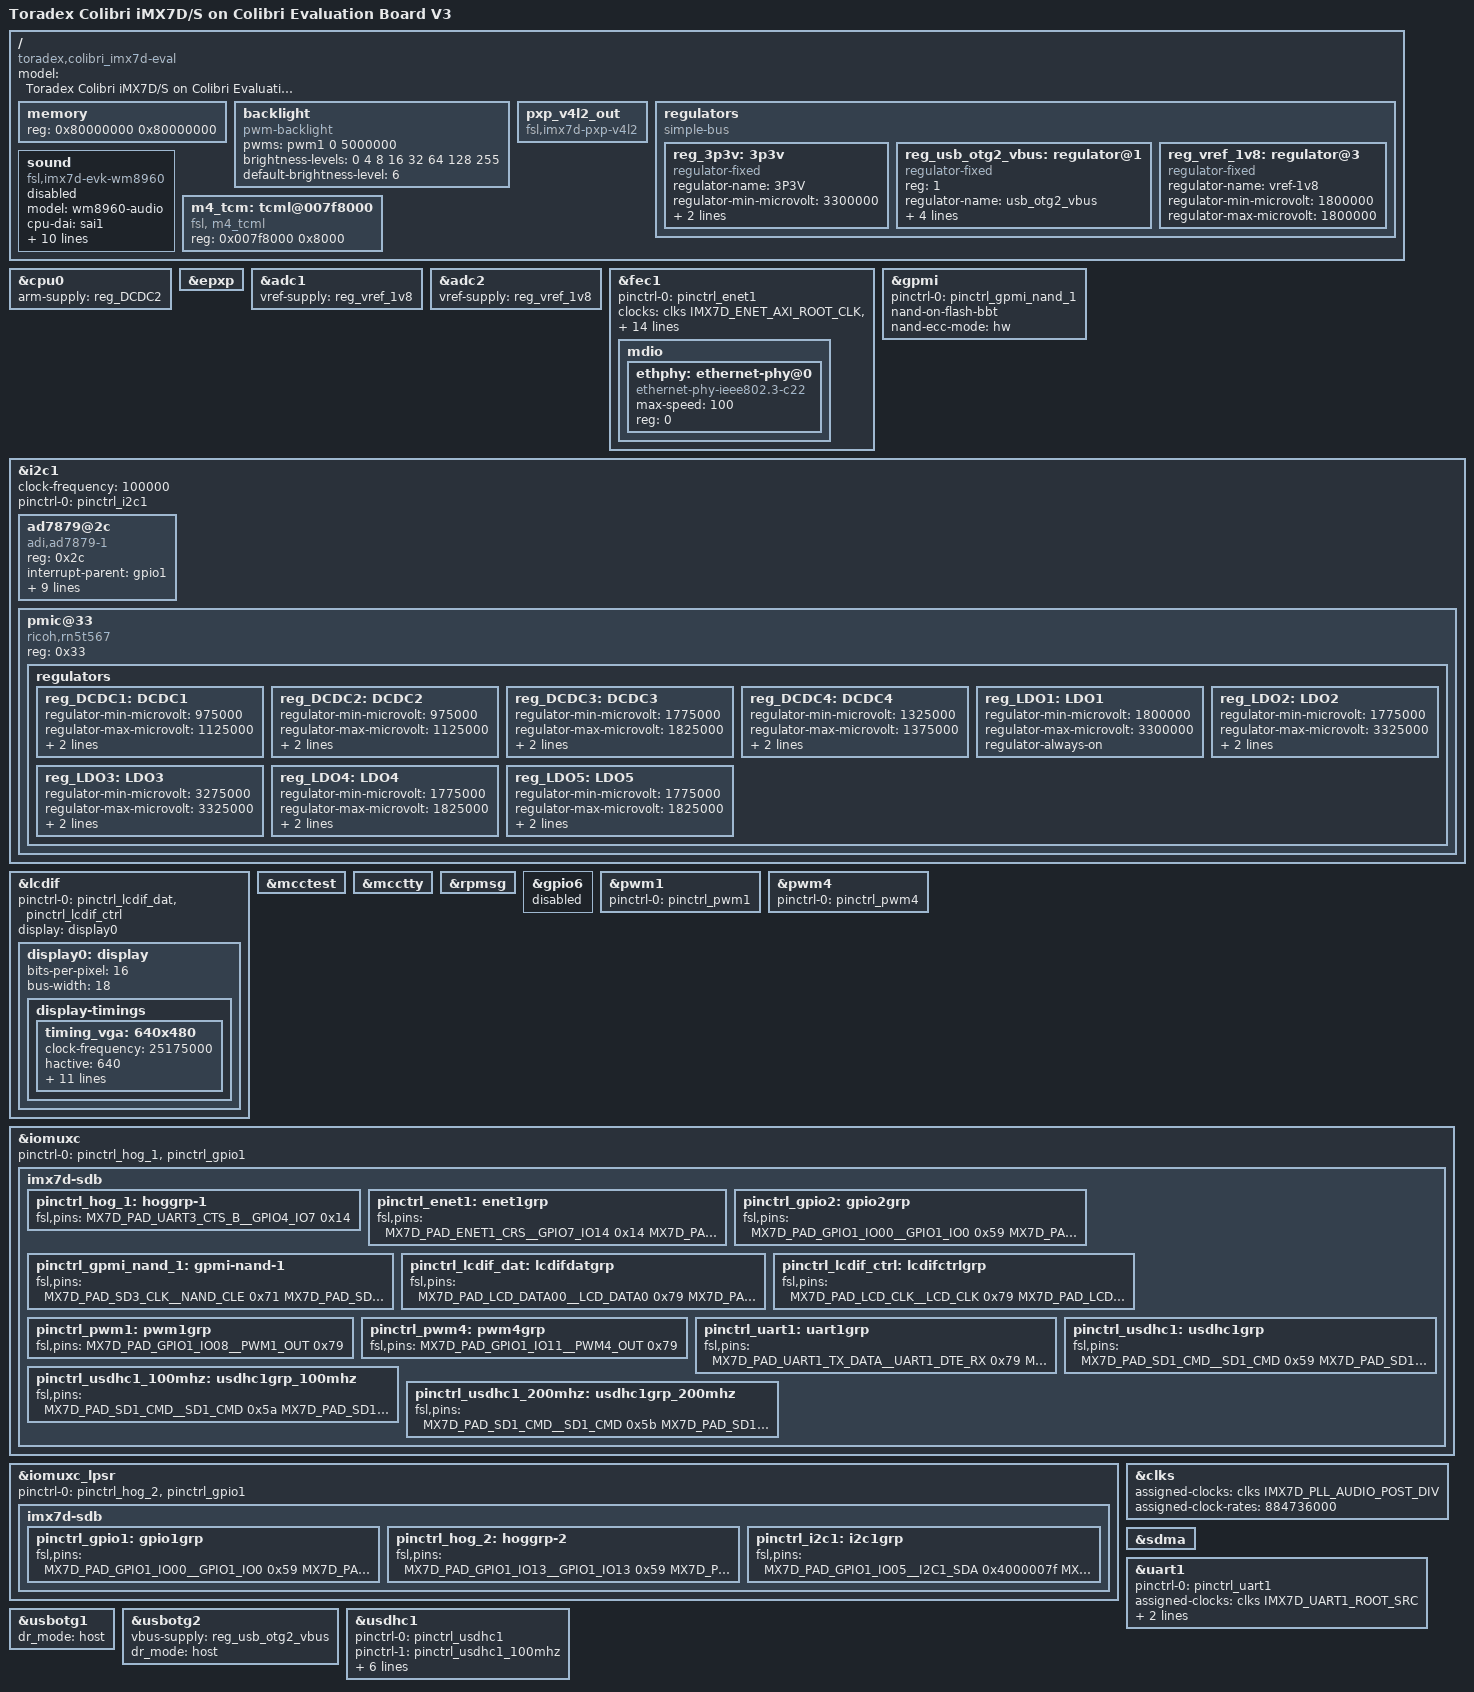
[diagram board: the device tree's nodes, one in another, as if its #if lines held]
/*
 * Copyright (C) 2015 Freescale Semiconductor, Inc.
 *
 * This program is free software; you can redistribute it and/or modify
 * it under the terms of the GNU General Public License version 2 as
 * published by the Free Software Foundation.
 */

/dts-v1/;

#include <dt-bindings/input/input.h>
#include "imx7d.dtsi"
//#define IMX7S 1
/ {
	model = "Toradex Colibri iMX7D/S on Colibri Evaluation Board V3";
	compatible = "toradex,colibri_imx7d-eval", "toradex,colibri_imx7d", "fsl,imx7d";

	memory {
		reg = <0x80000000 0x80000000>;
	};

#ifndef IMX7S
	backlight {
		compatible = "pwm-backlight";
		pwms = <&pwm1 0 5000000>;
		brightness-levels = <0 4 8 16 32 64 128 255>;
		default-brightness-level = <6>;
		status = "okay";
	};

	pxp_v4l2_out {
		compatible = "fsl,imx7d-pxp-v4l2", "fsl,imx6sx-pxp-v4l2", "fsl,imx6sl-pxp-v4l2";
		status = "okay";
	};
#endif
	regulators {
		compatible = "simple-bus";
		#address-cells = <1>;
		#size-cells = <0>;

		reg_3p3v: 3p3v {
			compatible = "regulator-fixed";
			regulator-name = "3P3V";
			regulator-min-microvolt = <3300000>;
			regulator-max-microvolt = <3300000>;
			regulator-always-on;
		};

		reg_usb_otg2_vbus: regulator@1 {
			compatible = "regulator-fixed";
			reg = <1>;
			regulator-name = "usb_otg2_vbus";
			regulator-min-microvolt = <5000000>;
			regulator-max-microvolt = <5000000>;
			gpio = <&gpio4 7 GPIO_ACTIVE_HIGH>;
			enable-active-low;
		};

		reg_vref_1v8: regulator@3 {
			compatible = "regulator-fixed";
			regulator-name = "vref-1v8";
			regulator-min-microvolt = <1800000>;
			regulator-max-microvolt = <1800000>;
		};
	};

#ifndef IMX7S
	sound {
		compatible = "fsl,imx7d-evk-wm8960",
			   "fsl,imx-audio-wm8960";
		model = "wm8960-audio";
		cpu-dai = <&sai1>;
		//audio-codec = <&codec>;
		codec-master;
		/* JD2: hp detect high for headphone*/
		hp-det = <2 0>;
		audio-routing =
			"LINPUT1", "Main MIC",
			"Main MIC", "MICB";
		assigned-clocks = <&clks IMX7D_AUDIO_MCLK_ROOT_SRC>,
				  <&clks IMX7D_AUDIO_MCLK_ROOT_CLK>;
		assigned-clock-parents = <&clks IMX7D_PLL_AUDIO_POST_DIV>;
		assigned-clock-rates = <0>, <12288000>;
		status = "disabled";
	};
#endif

	m4_tcm: tcml@007f8000 {
		compatible = "fsl, m4_tcml";
		reg = <0x007f8000 0x8000>;
	};
};

&cpu0 {
	arm-supply = <&reg_DCDC2>;
};
#ifndef IMX7S
&epxp {
	status = "okay";
};

&adc1 {
	vref-supply = <&reg_vref_1v8>;
	status = "okay";
};

&adc2 {
	vref-supply = <&reg_vref_1v8>;
	status = "okay";
};

&fec1 {
	pinctrl-names = "default";
	pinctrl-0 = <&pinctrl_enet1>;
	//pinctrl-assert-gpios = <&gpio_spi 5 GPIO_ACTIVE_HIGH>;
	clocks = <&clks IMX7D_ENET_AXI_ROOT_CLK>,
		<&clks IMX7D_ENET_AXI_ROOT_CLK>,
		<&clks IMX7D_ENET1_TIME_ROOT_CLK>,
		<&clks IMX7D_PLL_ENET_MAIN_50M_CLK>,
		<&clks IMX7D_ENET1_REF_ROOT_CLK>;
	clock-names = "ipg", "ahb", "ptp",
		"enet_clk_ref", "enet_out";

	assigned-clocks = <&clks IMX7D_ENET1_TIME_ROOT_SRC>,
			  <&clks IMX7D_ENET1_TIME_ROOT_CLK>;
	assigned-clock-parents = <&clks IMX7D_PLL_ENET_MAIN_100M_CLK>;
	assigned-clock-rates = <0>, <100000000>;
	phy-mode = "rmii";
	phy-handle = <&ethphy>;
	phy-supply = <&reg_LDO1>;
	fsl,magic-packet;
	status = "okay";

	mdio {
		#address-cells = <1>;
		#size-cells = <0>;
		ethphy: ethernet-phy@0 {
			compatible = "ethernet-phy-ieee802.3-c22";
			max-speed = <100>;
			reg = <0>;
		};
	};
};
#endif

#ifndef IMX7S
&gpmi {
	pinctrl-names = "default";
	pinctrl-0 = <&pinctrl_gpmi_nand_1>;
	status = "okay";
	nand-on-flash-bbt;

	nand-ecc-mode = "hw";
};
#endif

&i2c1 {
	clock-frequency = <100000>;
	pinctrl-names = "default";
	pinctrl-0 = <&pinctrl_i2c1>;
	status = "okay";

	ad7879@2c {
		compatible = "adi,ad7879-1";
		reg = <0x2c>;
		interrupt-parent = <&gpio1>;
		interrupts = <13 IRQ_TYPE_EDGE_FALLING>;
		resistance-plate-x = <120>;
		touchscreen-min-pressure = <0>;
		touchscreen-max-pressure = <4096>;
		first-conversion-delay = /bits/ 8 <3>; /* 512us */
		acquisition-time = /bits/ 8 <1>; /* 4us */
		median-filter-size = /bits/ 8 <2>; /* 8 measurements */
		averaging = /bits/ 8 <1>; /* 4 middle values */
		conversion-interval = /bits/ 8 <255>; /* 9.44ms */
	};

	pmic@33 {
		compatible = "ricoh,rn5t567";
		reg = <0x33>;

		regulators {
			reg_DCDC1: DCDC1 {  /* V1.0_SOC */
				regulator-min-microvolt =  <975000>;
				regulator-max-microvolt = <1125000>;
				regulator-boot-on;
				regulator-always-on;
			};

			reg_DCDC2: DCDC2 { /* V1.1_ARM */
				regulator-min-microvolt =  <975000>;
				regulator-max-microvolt = <1125000>;
				regulator-boot-on;
				regulator-always-on;
			};

			reg_DCDC3: DCDC3 { /* V1.8 */
				regulator-min-microvolt = <1775000>;
				regulator-max-microvolt = <1825000>;
				regulator-boot-on;
				regulator-always-on;
			};

			reg_DCDC4: DCDC4 { /* V1.35_DRAM */
				regulator-min-microvolt = <1325000>;
				regulator-max-microvolt = <1375000>;
				regulator-boot-on;
				regulator-always-on;
			};

			reg_LDO1: LDO1 { /* PWR_EN_+V3.3_ETH */
				regulator-min-microvolt = <1800000>;
				regulator-max-microvolt = <3300000>;
				regulator-always-on;
			};

			reg_LDO2: LDO2 { /* +V1.8_SD */
				regulator-min-microvolt = <1775000>;
				regulator-max-microvolt = <3325000>;
				regulator-boot-on;
				regulator-always-on;
			};

			reg_LDO3: LDO3 { /* PWR_EN_+V3.3_LPSR */
				regulator-min-microvolt = <3275000>;
				regulator-max-microvolt = <3325000>;
				regulator-boot-on;
				regulator-always-on;
			};

			reg_LDO4: LDO4 { /* V1.8_LPSR */
				regulator-min-microvolt = <1775000>;
				regulator-max-microvolt = <1825000>;
				regulator-boot-on;
				regulator-always-on;
			};

			reg_LDO5: LDO5 { /* PWR_EN_+V3.3 */
				regulator-min-microvolt = <1775000>;
				regulator-max-microvolt = <1825000>;
				regulator-boot-on;
				regulator-always-on;
			};
		};
	};

};

#ifndef IMX7S
&lcdif {
	pinctrl-names = "default";
	pinctrl-0 = <&pinctrl_lcdif_dat
		     &pinctrl_lcdif_ctrl>;
	//pinctrl-assert-gpios = <&gpio_spi 7 GPIO_ACTIVE_HIGH>;
	display = <&display0>;
	status = "okay";

	display0: display {
		bits-per-pixel = <16>;
		bus-width = <18>;

		display-timings {
/* not working, it takes the last element currently
			native-mode = <&timing_vga>;
*/
			/* Standard VGA timing */
			timing_vga: 640x480 {
				clock-frequency = <25175000>;
				hactive = <640>;
				vactive = <480>;
				hback-porch = <40>;
				hfront-porch = <24>;
				vback-porch = <32>;
				vfront-porch = <11>;
				hsync-len = <96>;
				vsync-len = <2>;

				de-active = <1>;
				hsync-active = <0>;
				vsync-active = <0>;
				pixelclk-active = <0>;
			};
#if 0
			/* WVGA Timing, e.g. EDT ET070080DH6 */
			timing_wvga: 800x480 {
				clock-frequency = <33260000>;
				hactive = <800>;
				vactive = <480>;
				hback-porch = <216>;
				hfront-porch = <40>;
				vback-porch = <35>;
				vfront-porch = <10>;
				hsync-len = <128>;
				vsync-len = <2>;

				de-active = <1>;
				hsync-active = <0>;
				vsync-active = <0>;
				pixelclk-active = <0>;
			};
			/* WVGA Timing, TouchRevolution Fusion 7" */
			timing_wvga2: 800x480pixclkact {
				clock-frequency = <33260000>;
				hactive = <800>;
				vactive = <480>;
				hback-porch = <216>;
				hfront-porch = <40>;
				vback-porch = <35>;
				vfront-porch = <10>;
				hsync-len = <128>;
				vsync-len = <2>;

				de-active = <1>;
				hsync-active = <0>;
				vsync-active = <0>;
				pixelclk-active = <1>;
			};
			/* Standard SVGA timing */
			timing_svga: 800x600 {
				clock-frequency = <40000000>;
				hactive = <800>;
				vactive = <600>;
				hback-porch = <88>;
				hfront-porch = <40>;
				vback-porch = <23>;
				vfront-porch = <1>;
				hsync-len = <128>;
				vsync-len = <4>;

				de-active = <1>;
				hsync-active = <1>;
				vsync-active = <1>;
				pixelclk-active = <0>;
			};
			/* TouchRevolution Fusion 10"/CLAA101NC05 10.1 inch */
			timing_wsvga: 1024x600 {
				clock-frequency = <48000000>;
				hactive = <1024>;
				vactive = <600>;
				hback-porch = <104>;
				hfront-porch = <43>;
				vback-porch = <24>;
				vfront-porch = <20>;
				hsync-len = <5>;
				vsync-len = <5>;

				de-active = <1>;
				hsync-active = <0>;
				vsync-active = <0>;
				pixelclk-active = <0>;
			};
			/* Standard XGA timing */
			timing_xga: 1024x768 {
				clock-frequency = <65000000>;
				hactive = <1024>;
				vactive = <768>;
				hback-porch = <160>;
				hfront-porch = <24>;
				vback-porch = <29>;
				vfront-porch = <3>;
				hsync-len = <136>;
				vsync-len = <6>;

				de-active = <1>;
				hsync-active = <0>;
				vsync-active = <0>;
				pixelclk-active = <0>;
			};
#endif
		};
	};
};

&mcctest{
	status = "okay";
};

&mcctty{
	status = "okay";
};

&rpmsg{
	status = "okay";
};

&gpio6{
	status = "disabled";
};

&pwm1 {
	pinctrl-names = "default";
	pinctrl-0 = <&pinctrl_pwm1>;
	status = "okay";
};

&pwm4 {
	pinctrl-names = "default";
	pinctrl-0 = <&pinctrl_pwm4>;
	status = "okay";
};
#endif
&iomuxc {
	pinctrl-names = "default";
	pinctrl-0 = <&pinctrl_hog_1>,<&pinctrl_gpio1>;

	imx7d-sdb {
#if 1
		pinctrl_hog_1: hoggrp-1 {
			fsl,pins = <
				MX7D_PAD_UART3_CTS_B__GPIO4_IO7	0x14
			>;
		};
#endif
		pinctrl_enet1: enet1grp {
			fsl,pins = <
				MX7D_PAD_ENET1_CRS__GPIO7_IO14			0x14 /* Weak pull down */
				MX7D_PAD_ENET1_RGMII_RX_CTL__ENET1_RGMII_RX_CTL	0x73
				MX7D_PAD_ENET1_RGMII_RD0__ENET1_RGMII_RD0	0x73
				MX7D_PAD_ENET1_RGMII_RD1__ENET1_RGMII_RD1	0x73
				MX7D_PAD_ENET1_RGMII_RXC__ENET1_RX_ER		0x73

				MX7D_PAD_ENET1_RGMII_TX_CTL__ENET1_RGMII_TX_CTL	0x73
				MX7D_PAD_ENET1_RGMII_TD0__ENET1_RGMII_TD0	0x73
				MX7D_PAD_ENET1_RGMII_TD1__ENET1_RGMII_TD1	0x73

                /* Avoid NMI's by disabling SION */
                MX7D_PAD_GPIO1_IO12__CCM_ENET_REF_CLK1        0x73
                /* use SION on second pin to get the clock to the MAC */
                MX7D_PAD_I2C1_SDA__CCM_ENET_REF_CLK1        0x40000073
				MX7D_PAD_SD2_CD_B__ENET1_MDIO			0x3
				MX7D_PAD_SD2_WP__ENET1_MDC			0x3
			>;
		};

		pinctrl_gpio2: gpio2grp {
			fsl,pins = <
				MX7D_PAD_GPIO1_IO00__GPIO1_IO0	0x59
				MX7D_PAD_GPIO1_IO01__GPIO1_IO1	0x59
				MX7D_PAD_GPIO1_IO03__GPIO1_IO3	0x59
			>;
		};

		pinctrl_gpmi_nand_1: gpmi-nand-1 {
			fsl,pins = <
				MX7D_PAD_SD3_CLK__NAND_CLE			0x71
				MX7D_PAD_SD3_CMD__NAND_ALE			0x71
				MX7D_PAD_SAI1_MCLK__NAND_WP_B		0x71
				MX7D_PAD_SAI1_TX_BCLK__NAND_CE0_B	0x71
				MX7D_PAD_SAI1_RX_DATA__NAND_CE1_B	0x71
				MX7D_PAD_SAI1_TX_DATA__NAND_READY_B	0x74
				MX7D_PAD_SD3_STROBE__NAND_RE_B		0x71
				MX7D_PAD_SD3_RESET_B__NAND_WE_B		0x71
				MX7D_PAD_SD3_DATA0__NAND_DATA00		0x71
				MX7D_PAD_SD3_DATA1__NAND_DATA01		0x71
				MX7D_PAD_SD3_DATA2__NAND_DATA02		0x71
				MX7D_PAD_SD3_DATA3__NAND_DATA03		0x71
				MX7D_PAD_SD3_DATA4__NAND_DATA04		0x71
				MX7D_PAD_SD3_DATA5__NAND_DATA05		0x71
				MX7D_PAD_SD3_DATA6__NAND_DATA06		0x71
				MX7D_PAD_SD3_DATA7__NAND_DATA07		0x71

			>;
		};

		pinctrl_lcdif_dat: lcdifdatgrp {
			fsl,pins = <
				MX7D_PAD_LCD_DATA00__LCD_DATA0	0x79
				MX7D_PAD_LCD_DATA01__LCD_DATA1	0x79
				MX7D_PAD_LCD_DATA02__LCD_DATA2	0x79
				MX7D_PAD_LCD_DATA03__LCD_DATA3	0x79
				MX7D_PAD_LCD_DATA04__LCD_DATA4	0x79
				MX7D_PAD_LCD_DATA05__LCD_DATA5	0x79
				MX7D_PAD_LCD_DATA06__LCD_DATA6	0x79
				MX7D_PAD_LCD_DATA07__LCD_DATA7	0x79
				MX7D_PAD_LCD_DATA08__LCD_DATA8	0x79
				MX7D_PAD_LCD_DATA09__LCD_DATA9	0x79
				MX7D_PAD_LCD_DATA10__LCD_DATA10	0x79
				MX7D_PAD_LCD_DATA11__LCD_DATA11	0x79
				MX7D_PAD_LCD_DATA12__LCD_DATA12	0x79
				MX7D_PAD_LCD_DATA13__LCD_DATA13	0x79
				MX7D_PAD_LCD_DATA14__LCD_DATA14	0x79
				MX7D_PAD_LCD_DATA15__LCD_DATA15	0x79
				MX7D_PAD_LCD_DATA16__LCD_DATA16	0x79
				MX7D_PAD_LCD_DATA17__LCD_DATA17	0x79
			>;
		};

		pinctrl_lcdif_ctrl: lcdifctrlgrp {
			fsl,pins = <
				MX7D_PAD_LCD_CLK__LCD_CLK	0x79
				MX7D_PAD_LCD_ENABLE__LCD_ENABLE	0x79
				MX7D_PAD_LCD_VSYNC__LCD_VSYNC	0x79
				MX7D_PAD_LCD_HSYNC__LCD_HSYNC	0x79
			>;
		};

		pinctrl_pwm1: pwm1grp {
			fsl,pins = <
				MX7D_PAD_GPIO1_IO08__PWM1_OUT 0x79
			>;
		};

		pinctrl_pwm4: pwm4grp {
			fsl,pins = <
				MX7D_PAD_GPIO1_IO11__PWM4_OUT 0x79
			>;
		};

		pinctrl_uart1: uart1grp {
			fsl,pins = <
				MX7D_PAD_UART1_TX_DATA__UART1_DTE_RX 0x79
				MX7D_PAD_UART1_RX_DATA__UART1_DTE_TX 0x79
			>;
		};

		pinctrl_usdhc1: usdhc1grp {
			fsl,pins = <
				MX7D_PAD_SD1_CMD__SD1_CMD	0x59
				MX7D_PAD_SD1_CLK__SD1_CLK	0x19
				MX7D_PAD_SD1_DATA0__SD1_DATA0	0x59
				MX7D_PAD_SD1_DATA1__SD1_DATA1	0x59
				MX7D_PAD_SD1_DATA2__SD1_DATA2	0x59
				MX7D_PAD_SD1_DATA3__SD1_DATA3	0x59
			>;
		};

		pinctrl_usdhc1_100mhz: usdhc1grp_100mhz {
			fsl,pins = <
				MX7D_PAD_SD1_CMD__SD1_CMD	0x5a
				MX7D_PAD_SD1_CLK__SD1_CLK	0x1a
				MX7D_PAD_SD1_DATA0__SD1_DATA0	0x5a
				MX7D_PAD_SD1_DATA1__SD1_DATA1	0x5a
				MX7D_PAD_SD1_DATA2__SD1_DATA2	0x5a
				MX7D_PAD_SD1_DATA3__SD1_DATA3	0x5a
			>;
		};

		pinctrl_usdhc1_200mhz: usdhc1grp_200mhz {
			fsl,pins = <
				MX7D_PAD_SD1_CMD__SD1_CMD	0x5b
				MX7D_PAD_SD1_CLK__SD1_CLK	0x1b
				MX7D_PAD_SD1_DATA0__SD1_DATA0	0x5b
				MX7D_PAD_SD1_DATA1__SD1_DATA1	0x5b
				MX7D_PAD_SD1_DATA2__SD1_DATA2	0x5b
				MX7D_PAD_SD1_DATA3__SD1_DATA3	0x5b
			>;
		};
	};
};

&iomuxc_lpsr {
	pinctrl-names = "default";
	pinctrl-0 = <&pinctrl_hog_2>, <&pinctrl_gpio1>;

	imx7d-sdb {
		pinctrl_gpio1: gpio1grp {
			fsl,pins = <
				MX7D_PAD_GPIO1_IO00__GPIO1_IO0	0x59
				MX7D_PAD_GPIO1_IO01__GPIO1_IO1	0x59
				MX7D_PAD_GPIO1_IO03__GPIO1_IO3	0x59
			>;
		};
		pinctrl_hog_2: hoggrp-2 {
			fsl,pins = <
				MX7D_PAD_GPIO1_IO13__GPIO1_IO13	0x59 /* PWR_INT */
				MX7D_PAD_GPIO1_IO00__GPIO1_IO0  0x79 /* CD */
			>;
		};
		pinctrl_i2c1: i2c1grp {
			fsl,pins = <
				MX7D_PAD_GPIO1_IO05__I2C1_SDA	0x4000007f
				MX7D_PAD_GPIO1_IO04__I2C1_SCL	0x4000007f
			>;
		};
	};
};

&clks {
	assigned-clocks = <&clks IMX7D_PLL_AUDIO_POST_DIV>;
	assigned-clock-rates = <884736000>;
};

&sdma {
	status = "okay";
};

&uart1 {
	pinctrl-names = "default";
	pinctrl-0 = <&pinctrl_uart1>;
	assigned-clocks = <&clks IMX7D_UART1_ROOT_SRC>;
	assigned-clock-parents = <&clks IMX7D_OSC_24M_CLK>;
	// fsl,uart-has-rtscts;
	fsl,dte-mode;
	status = "okay";
};

&usbotg1 {
	dr_mode = "host";
	status = "okay";
};
#ifndef IMX7S
&usbotg2 {
	vbus-supply = <&reg_usb_otg2_vbus>;
	dr_mode = "host";
	status = "okay";
};
#endif

/* The define SD_1_8 allows to use the SD interface at a higher speed mode
 * if the card supports it. For this the signaling voltage is switched from
 * 3.3V to 1.8V under the usdhc1's drivers control.
 * All pins supplied with NVCC_SD1 must be able to cope with this
 * and must (MUST!!!) not be driven with a voltage higher than 1.8V.
 */
/* #define SD_1_8 */

&usdhc1 {
#ifdef SD_1_8
	pinctrl-names = "default", "state_100mhz", "state_200mhz";
	pinctrl-0 = <&pinctrl_usdhc1>;
	pinctrl-1 = <&pinctrl_usdhc1_100mhz>;
	pinctrl-2 = <&pinctrl_usdhc1_200mhz>;
	vmmc-supply = <&reg_3p3v>;
	vqmmc-supply = <&reg_LDO2>;
#else
	pinctrl-names = "default";
	pinctrl-0 = <&pinctrl_usdhc1>;
	no-1-8-v;
#endif
	enable-sdio-wakeup;
	keep-power-in-suspend;
	status = "okay";
	tuning-step = <2>;
};
